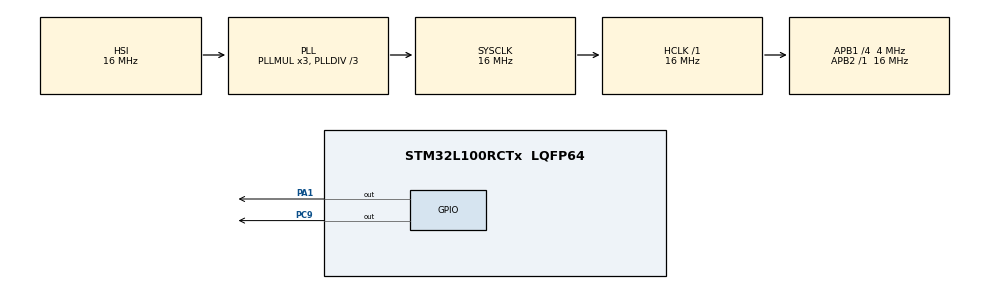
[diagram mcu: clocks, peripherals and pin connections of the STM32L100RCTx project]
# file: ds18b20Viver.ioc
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Mcu.Family=STM32L1
Mcu.Name=STM32L100RCTx
Mcu.Package=LQFP64
NVIC.PriorityGroup=NVIC_PRIORITYGROUP_4
PA1.Signal=GPIO_Output
PC9.Signal=GPIO_Output
PH0-OSC_IN.Mode=HSE-External-Oscillator
PH0-OSC_IN.Signal=RCC_OSC_IN
PH1-OSC_OUT.Mode=HSE-External-Oscillator
PH1-OSC_OUT.Signal=RCC_OSC_OUT
ProjectManager.HeapSize=0x200
ProjectManager.StackSize=0x400
ProjectManager.TargetToolchain=STM32CubeIDE
RCC.48MHZClocksFreq_Value=24000000
RCC.AHBFreq_Value=16000000
RCC.APB1CLKDivider=RCC_HCLK_DIV4
RCC.APB1Freq_Value=4000000
RCC.APB1TimFreq_Value=8000000
RCC.APB2Freq_Value=16000000
RCC.APB2TimFreq_Value=16000000
RCC.HCLKFreq_Value=16000000
RCC.HSE_VALUE=8000000
RCC.HSI_VALUE=16000000
RCC.LSE_VALUE=32768
RCC.MSI_VALUE=2097000
RCC.PLLDIV=RCC_PLL_DIV3
RCC.SYSCLKFreq_VALUE=16000000
RCC.SYSCLKSource=RCC_SYSCLKSOURCE_PLLCLK
RCC.VCOOutputFreq_Value=48000000
TIM6.Period=0xffff-1
TIM6.Prescaler=8-1
VP_TIM6_VS_ClockSourceINT.Mode=Enable_Timer
board=custom

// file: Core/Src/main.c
/* USER CODE BEGIN Header */
/**
  ******************************************************************************
  * @file           : main.c
  * @brief          : Main program body
  ******************************************************************************
  * @attention
  *
  * Copyright (c) 2022 STMicroelectronics.
  * All rights reserved.
  *
  * This software is licensed under terms that can be found in the LICENSE file
  * in the root directory of this software component.
  * If no LICENSE file comes with this software, it is provided AS-IS.
  *
  ******************************************************************************
  */
/* USER CODE END Header */
#include "main.h"

/* USER CODE BEGIN Includes */
#include "stdio.h"

/* USER CODE END Includes */

 TIM_HandleTypeDef htim6;

void SystemClock_Config(void);
static void MX_GPIO_Init(void);
static void MX_TIM6_Init(void);

/* USER CODE BEGIN 0 */
void delay (uint16_t time)
{
	/* change your code here for the delay in microseconds */
	__HAL_TIM_SET_COUNTER(&htim6, 0);
	while ((__HAL_TIM_GET_COUNTER(&htim6))<time);
}

uint8_t Rh_byte1, Rh_byte2, Temp_byte1, Temp_byte2, Temp_byte3, Temp_byte4, Temp_byte5, Temp_byte6, Temp_byte7, Temp_byte8, Temp_byte9;
uint16_t SUM, RH, TEMP;

float Temperature = 0;
float Humidity = 0;
uint8_t Presence = 0;

void Set_Pin_Output (GPIO_TypeDef *GPIOx, uint16_t GPIO_Pin)
{
	GPIO_InitTypeDef GPIO_InitStruct = {0};
	GPIO_InitStruct.Pin = GPIO_Pin;
	GPIO_InitStruct.Mode = GPIO_MODE_OUTPUT_PP;
	GPIO_InitStruct.Speed = GPIO_SPEED_FREQ_LOW;
	HAL_GPIO_Init(GPIOx, &GPIO_InitStruct);
}

void Set_Pin_Input (GPIO_TypeDef *GPIOx, uint16_t GPIO_Pin)
{
	GPIO_InitTypeDef GPIO_InitStruct = {0};
	GPIO_InitStruct.Pin = GPIO_Pin;
	GPIO_InitStruct.Mode = GPIO_MODE_INPUT;
	GPIO_InitStruct.Pull = GPIO_PULLUP;
	HAL_GPIO_Init(GPIOx, &GPIO_InitStruct);
}

#define DS18B20_PORT GPIOA
#define DS18B20_PIN GPIO_PIN_1

uint8_t DS18B20_Start (void)
{
	uint8_t Response = 0;
	Set_Pin_Output(DS18B20_PORT, DS18B20_PIN);   // set the pin as output
	HAL_GPIO_WritePin (DS18B20_PORT, DS18B20_PIN, 0);  // pull the pin low
	delay (480);   // delay according to datasheet
	//HAL_GPIO_WritePin (DS18B20_PORT, DS18B20_PIN, 1);

	Set_Pin_Input(DS18B20_PORT, DS18B20_PIN);    // set the pin as input
	delay (80);    // delay according to datasheet

	if (!(HAL_GPIO_ReadPin (DS18B20_PORT, DS18B20_PIN))) Response = 1;    // if the pin is low i.e the presence pulse is detected
	else Response = -1;

	delay (400); // 480 us delay totally.

	return Response;
}

void DS18B20_Write (uint8_t data)
{
	Set_Pin_Output(DS18B20_PORT, DS18B20_PIN);  // set as output

	for (int i=0; i<8; i++)
	{

		if ((data & (1<<i))!=0)  // if the bit is high
		{
			// write 1

			Set_Pin_Output(DS18B20_PORT, DS18B20_PIN);  // set as output
			HAL_GPIO_WritePin (DS18B20_PORT, DS18B20_PIN, 0);  // pull the pin LOW
			delay (1);  // wait for 1 us

			Set_Pin_Input(DS18B20_PORT, DS18B20_PIN);  // set as input
			delay (50);  // wait for 60 us
		}

		else  // if the bit is low
		{
			// write 0

			Set_Pin_Output(DS18B20_PORT, DS18B20_PIN);
			HAL_GPIO_WritePin (DS18B20_PORT, DS18B20_PIN, 0);  // pull the pin LOW
			delay (50);  // wait for 60 us

			Set_Pin_Input(DS18B20_PORT, DS18B20_PIN);
		}
	}
}

uint8_t DS18B20_Read (void)
{
	uint8_t value=0;

	Set_Pin_Input(DS18B20_PORT, DS18B20_PIN);

	for (int i=0;i<8;i++)
	{
		Set_Pin_Output(DS18B20_PORT, DS18B20_PIN);   // set as output

		HAL_GPIO_WritePin (DS18B20_PORT, DS18B20_PIN, 0);  // pull the data pin LOW
		delay (1);  // wait for > 1us

		Set_Pin_Input(DS18B20_PORT, DS18B20_PIN);  // set as input
		if (HAL_GPIO_ReadPin (DS18B20_PORT, DS18B20_PIN))  // if the pin is HIGH
		{
			value |= 1<<i;  // read = 1
		}
		delay (50);  // wait for 60 us
	}
	return value;
}

/* USER CODE END 0 */

int main(void)
{

  /* MCU Configuration--------------------------------------------------------*/

  /* Reset of all peripherals, Initializes the Flash interface and the Systick. */
  HAL_Init();

  /* Configure the system clock */
  SystemClock_Config();

  /* Initialize all configured peripherals */
  MX_GPIO_Init();
  MX_TIM6_Init();
  /* USER CODE BEGIN 2 */
  HAL_TIM_Base_Start(&htim6);

  /*while (1)
    {
	  HAL_GPIO_WritePin(GPIOC, GPIO_PIN_9, 1);
	  	  delay(480);
	  	  HAL_GPIO_WritePin (GPIOC, GPIO_PIN_9, 0);
	  	 delay(480);

    }*/

  /* USER CODE END 2 */

  /* Infinite loop */
  while (1)
  {

    /* USER CODE BEGIN 3 */

	      Presence = DS18B20_Start ();
	  	  HAL_Delay (1);
	  	  DS18B20_Write (0xCC);  // skip ROM
	  	  DS18B20_Write (0x44);  // convert t
	  	  HAL_Delay (2000);

	  	  Presence = DS18B20_Start ();
	        HAL_Delay(1);
	        DS18B20_Write (0xCC);  // skip ROM
	        DS18B20_Write (0xBE);  // Read Scratch-pad

	      Temp_byte1 = DS18B20_Read();

	      Temp_byte2 = DS18B20_Read();
	      Temp_byte3 = DS18B20_Read();
	      Temp_byte4 = DS18B20_Read();
	      Temp_byte5 = DS18B20_Read();
	      Temp_byte6 = DS18B20_Read();
	      Temp_byte7 = DS18B20_Read();
	      Temp_byte8 = DS18B20_Read();
	      Temp_byte9 = DS18B20_Read();

	  	  TEMP = (Temp_byte2<<8)|Temp_byte1;
	  	  Temperature = (float)TEMP/16;

	  	  HAL_Delay(1000);
  }
  /* USER CODE END 3 */
}

void SystemClock_Config(void)
{
  RCC_OscInitTypeDef RCC_OscInitStruct = {0};
  RCC_ClkInitTypeDef RCC_ClkInitStruct = {0};

  /** Configure the main internal regulator output voltage
  */
  __HAL_PWR_VOLTAGESCALING_CONFIG(PWR_REGULATOR_VOLTAGE_SCALE1);

  /** Initializes the RCC Oscillators according to the specified parameters
  * in the RCC_OscInitTypeDef structure.
  */
  RCC_OscInitStruct.OscillatorType = RCC_OSCILLATORTYPE_HSI;
  RCC_OscInitStruct.HSIState = RCC_HSI_ON;
  RCC_OscInitStruct.HSICalibrationValue = RCC_HSICALIBRATION_DEFAULT;
  RCC_OscInitStruct.PLL.PLLState = RCC_PLL_ON;
  RCC_OscInitStruct.PLL.PLLSource = RCC_PLLSOURCE_HSI;
  RCC_OscInitStruct.PLL.PLLMUL = RCC_PLL_MUL3;
  RCC_OscInitStruct.PLL.PLLDIV = RCC_PLL_DIV3;
  if (HAL_RCC_OscConfig(&RCC_OscInitStruct) != HAL_OK)
  {
    Error_Handler();
  }

  /** Initializes the CPU, AHB and APB buses clocks
  */
  RCC_ClkInitStruct.ClockType = RCC_CLOCKTYPE_HCLK|RCC_CLOCKTYPE_SYSCLK
                              |RCC_CLOCKTYPE_PCLK1|RCC_CLOCKTYPE_PCLK2;
  RCC_ClkInitStruct.SYSCLKSource = RCC_SYSCLKSOURCE_PLLCLK;
  RCC_ClkInitStruct.AHBCLKDivider = RCC_SYSCLK_DIV1;
  RCC_ClkInitStruct.APB1CLKDivider = RCC_HCLK_DIV4;
  RCC_ClkInitStruct.APB2CLKDivider = RCC_HCLK_DIV1;

  if (HAL_RCC_ClockConfig(&RCC_ClkInitStruct, FLASH_LATENCY_0) != HAL_OK)
  {
    Error_Handler();
  }
}

static void MX_TIM6_Init(void)
{

  TIM_MasterConfigTypeDef sMasterConfig = {0};

  htim6.Instance = TIM6;
  htim6.Init.Prescaler = 8-1;
  htim6.Init.CounterMode = TIM_COUNTERMODE_UP;
  htim6.Init.Period = 0xffff-1;
  htim6.Init.AutoReloadPreload = TIM_AUTORELOAD_PRELOAD_DISABLE;
  if (HAL_TIM_Base_Init(&htim6) != HAL_OK)
  {
    Error_Handler();
  }
  sMasterConfig.MasterOutputTrigger = TIM_TRGO_RESET;
  sMasterConfig.MasterSlaveMode = TIM_MASTERSLAVEMODE_DISABLE;
  if (HAL_TIMEx_MasterConfigSynchronization(&htim6, &sMasterConfig) != HAL_OK)
  {
    Error_Handler();
  }

}

static void MX_GPIO_Init(void)
{
  GPIO_InitTypeDef GPIO_InitStruct = {0};

  /* GPIO Ports Clock Enable */
  __HAL_RCC_GPIOH_CLK_ENABLE();
  __HAL_RCC_GPIOA_CLK_ENABLE();
  __HAL_RCC_GPIOC_CLK_ENABLE();

  /*Configure GPIO pin Output Level */
  HAL_GPIO_WritePin(GPIOA, GPIO_PIN_1, GPIO_PIN_RESET);

  /*Configure GPIO pin Output Level */
  HAL_GPIO_WritePin(GPIOC, GPIO_PIN_9, GPIO_PIN_RESET);

  /*Configure GPIO pin : PA1 */
  GPIO_InitStruct.Pin = GPIO_PIN_1;
  GPIO_InitStruct.Mode = GPIO_MODE_OUTPUT_PP;
  GPIO_InitStruct.Pull = GPIO_NOPULL;
  GPIO_InitStruct.Speed = GPIO_SPEED_FREQ_LOW;
  HAL_GPIO_Init(GPIOA, &GPIO_InitStruct);

  /*Configure GPIO pin : PC9 */
  GPIO_InitStruct.Pin = GPIO_PIN_9;
  GPIO_InitStruct.Mode = GPIO_MODE_OUTPUT_PP;
  GPIO_InitStruct.Pull = GPIO_NOPULL;
  GPIO_InitStruct.Speed = GPIO_SPEED_FREQ_LOW;
  HAL_GPIO_Init(GPIOC, &GPIO_InitStruct);

}

void Error_Handler(void)
{
  __disable_irq();
  while (1)
  {
  }
}
